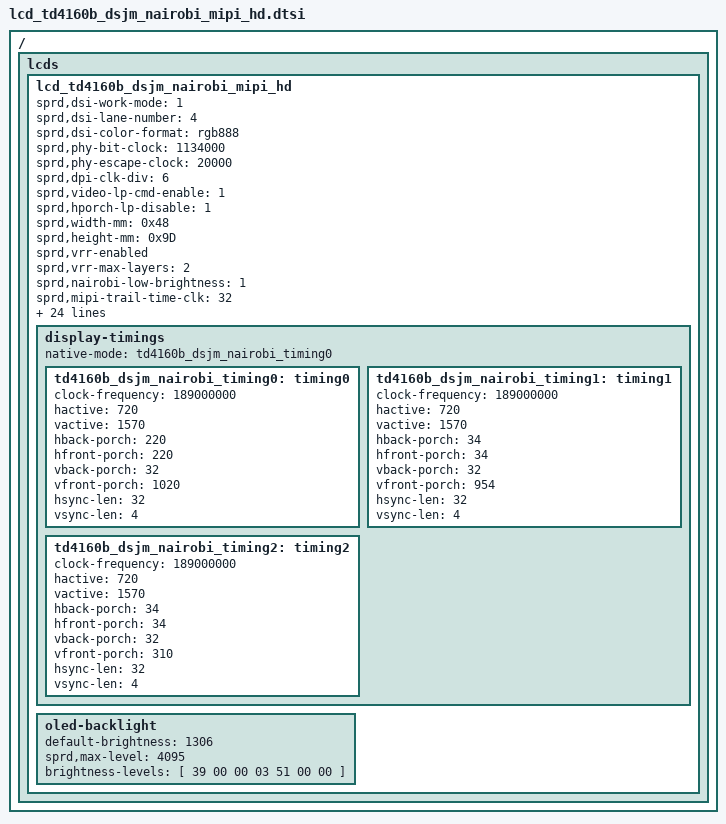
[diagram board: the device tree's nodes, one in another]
/*
 * R61350 Truly LCD config dtsi file for spreadtrum
 *
 * Copyright (C) 2018, Spreadtrum Communications Inc.
 *
 * SPDX-License-Identifier: (GPL-2.0+ OR MIT)
 */

/ {
	fragment {
		target-path = "/";
		__overlay__ {
			lcds {
				lcd_td4160b_dsjm_nairobi_mipi_hd: lcd_td4160b_dsjm_nairobi_mipi_hd {

					sprd,dsi-work-mode = <1>; /* video burst mode*/
					sprd,dsi-lane-number = <4>;
					sprd,dsi-color-format = "rgb888";

					sprd,phy-bit-clock = <1134000>; /* kbps */
					sprd,phy-escape-clock = <20000>;/* kHz */
					sprd,dpi-clk-div = <6>;
					sprd,video-lp-cmd-enable = <1>;
					sprd,hporch-lp-disable = <1>;

					sprd,width-mm = <0x48>;
					sprd,height-mm = <0x9D>;
					sprd,vrr-enabled;
					sprd,vrr-max-layers = <2>;

					sprd,nairobi-low-brightness = <1>;
					sprd,mipi-trail-time-clk = <32>;

					sprd,esd-check-enable = <1>;
					sprd,esd-check-mode = <1>;
					sprd,esd-check-period = <5000>;
					//sprd,esd-check-register = <0x0A>;
					//sprd,esd-check-value = <0x9C>;

					sprd,power-i2c-bus = <4>;
					sprd,power-i2c-addr = <0x3e>;
					sprd,power-i2c-reg = [00 01 03];
					sprd,power-i2c-val = [14 14 33];

					sprd,reset-on-sequence = <1 5>, <0 5>, <1 30>;
					sprd,reset-off-sequence = <0 5>;

					sprd,ovt-tp-aod-support = <1>;
					sprd,ovt-tp-reset-gpio = <1>;
				/*
                 * Use 4 bits number for descripting video lp mode, and it can be combined used.
                 * BIT(0): allow vactive enter lp;
                 * BIT(1): allow vfp enter lp;
                 * BIT(2): allow vbp enter lp;
                 * BIT(3): allow vsa enter lp;
                 * For example:
                 * If we need vfp & vbp enter lp, we can calculate this value as a result of BIT(1) | BIT(2)
                 * And we get the result of 3 and set this value to lcd dt property sprd,video-lp-en-mode.
                 * If we need all stage can enter lp, we can calculate this value as a result of BIT(0) | BIT(1) | BIT(2) | BIT(3).
                 * And we get the result of 15 and set this value to lcd dt property sprd,video-lp-en-mode.
                 */
                sprd,video-lp-en-mode = <2>;
					sprd,use-dcs-write;
					sprd,initial-command = [
					29 00 00 02 B0 04
					29 00 00 02 D6 00
					29 00 00 03 C1 30 81
					29 00 00 07 BA 06 90 09 00 0b 00
					29 00 00 19 CE 16 10 42 4b 4e 5c 60 62 7f 8b 9f af b6 ba bf c4 c9 0f 06 04 04 00 04 8c
					29 00 00 09 EB 0B 90 B9 00 01 01 00 00
					29 00 00 22 ED 01 02 00 00 00 00 00 00 65 37 10 00 00 00 00 00 00 00 00 00 00 00 02 b0 00 00 00 00 00 00 40 10 00
					29 00 00 04 D2 12 00 00  //esd-check method
					29 00 00 02 35 00
					29 00 00 02 51 00
					29 00 00 02 53 24
					29 00 00 02 55 01
					29 00 00 02 B0 03
					05 50 00 01 11
					05 14 00 01 29
						];

					sprd,sleep-in-command = [
						05 14 00 01 28
						05 78 00 01 10
						];

					sprd,sleep-out-command = [
						05 14 00 01 11
						05 78 00 01 29
						];

					sprd,cabc-off-command = [
						39 00 00 02 55 03
						];
					sprd,cabc-ui-command = [
						39 00 00 02 55 13
						];
					sprd,cabc-still-command = [
						39 00 00 02 55 23
						];
					sprd,cabc-moving-command = [
						39 00 00 02 55 33
						];

					display-timings {
						native-mode = <&td4160b_dsjm_nairobi_timing0>;

						td4160b_dsjm_nairobi_timing0: timing0 {
							clock-frequency = <189000000>;
							hactive = <720>;
							vactive = <1570>;
							hback-porch = <220>;
							hfront-porch = <220>;
							vback-porch = <32>;
							vfront-porch = <1020>;
							hsync-len = <32>;
							vsync-len = <4>;
						};
						td4160b_dsjm_nairobi_timing1: timing1 {
							clock-frequency = <189000000>;
							hactive = <720>;
							vactive = <1570>;
							hback-porch = <34>;
							hfront-porch = <34>;
							vback-porch = <32>;
							vfront-porch = <954>;
							hsync-len = <32>;
							vsync-len = <4>;
						};
						td4160b_dsjm_nairobi_timing2: timing2 {
							clock-frequency = <189000000>;
							hactive = <720>;
							vactive = <1570>;
							hback-porch = <34>;
							hfront-porch = <34>;
							vback-porch = <32>;
							vfront-porch = <310>;
							hsync-len = <32>;
							vsync-len = <4>;
						};
					};

					oled-backlight {
						default-brightness = <1306>;
						sprd,max-level = <4095>;
						brightness-levels = [
							39 00 00 03 51 00 00
						];
					};
				};
			};
		};
	};
};
